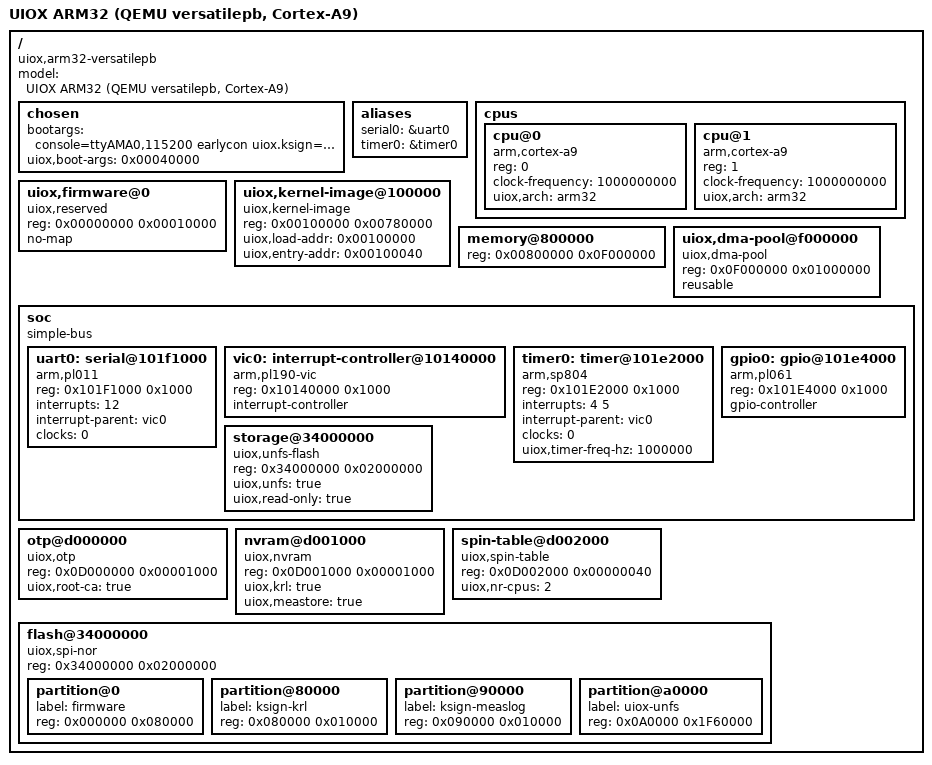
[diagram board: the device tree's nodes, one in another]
/*
 * uiox-arm32.dts — UIOX device tree source for ARM32
 *
 * Target: ARMv7-A, QEMU -machine versatilepb, Cortex-A9
 * Interrupt controller: PL190 VIC @ 0x10140000 (versatilepb)
 * Timer: SP804 dual timer @ 0x101E2000
 *
 * UIOX-specific regions (from UIOX source cross-references):
 *   kernel load/entry  ← uiox_ksign_image.h
 *   OTP/KRL/NVRAM      ← uiox_ksign_key.h
 *   SMP spin-table     ← uiox_cpu_hw.h
 *
 * Build:  make arm32      (or: dtc -I dts -O dtb -o uiox-arm32.dtb uiox-arm32.dts)
 *
 * Conventions: unit addresses are bare lowercase hex (no "0x", no leading 0s).
 */

/dts-v1/;

/ {
    model = "UIOX ARM32 (QEMU versatilepb, Cortex-A9)";
    compatible = "uiox,arm32-versatilepb";

    #address-cells = <1>;
    #size-cells    = <1>;

    chosen {
        /* UIOX bootargs — replaces the hardcoded string in
         * uiox_boot_main.c (UIOX_CMDLINE). */
        bootargs = "console=ttyAMA0,115200 earlycon uiox.ksign=on";
        /* Physical address the bootloader hands the kernel. */
        uiox,boot-args = <0x00040000>;
    };

    aliases {
        serial0 = &uart0;
        timer0  = &timer0;
    };

    /* ── CPUs ───────────────────────────────────────────────────── */
    cpus {
        #address-cells = <1>;
        #size-cells    = <0>;

        cpu@0 {
            device_type  = "cpu";
            compatible   = "arm,cortex-a9";
            reg          = <0>;
            clock-frequency = <1000000000>;   /* 1 GHz, QEMU default */
            uiox,arch    = "arm32";
        };

        cpu@1 {
            device_type  = "cpu";
            compatible   = "arm,cortex-a9";
            reg          = <1>;
            clock-frequency = <1000000000>;
            uiox,arch    = "arm32";
        };
    };

    /* ── Memory ─────────────────────────────────────────────────── */

    /* Trusted firmware / secure monitor region */
    uiox,firmware@0 {
        compatible = "uiox,reserved";
        reg = <0x00000000 0x00010000>;   /* 64 KiB secure/BL       */
        no-map;
    };

    /* UIOX kernel image — ksign verified (load = entry - 0x40) */
    uiox,kernel-image@100000 {
        compatible = "uiox,kernel-image";
        reg = <0x00100000 0x00780000>;   /* 7.5 MiB                */
        uiox,load-addr  = <0x00100000>;
        uiox,entry-addr = <0x00100040>;
    };

    /* OS usable RAM — placed above the kernel image so the addresses
     * do not collide (the earlier tree overlapped both at 0x100000). */
    memory@800000 {
        device_type = "memory";
        reg = <0x00800000 0x0F000000>;   /* 240 MiB (versatilepb)  */
    };

    /* DMA coherent pool */
    uiox,dma-pool@f000000 {
        compatible = "uiox,dma-pool";
        reg = <0x0F000000 0x01000000>;   /* 16 MiB                 */
        reusable;
    };

    /* ── SoC peripherals ────────────────────────────────────────── */
    soc {
        #address-cells = <1>;
        #size-cells    = <1>;
        compatible     = "simple-bus";
        ranges;

        /* PL011 UART0 — QEMU versatilepb @ 0x101F1000 */
        uart0: serial@101f1000 {
            compatible        = "arm,pl011", "arm,primecell";
            reg               = <0x101F1000 0x1000>;
            interrupts        = <12>;
            interrupt-parent  = <&vic0>;
            clocks            = <0>;
            status            = "okay";
        };

        /* PL190 Vectored Interrupt Controller @ 0x10140000 */
        vic0: interrupt-controller@10140000 {
            compatible        = "arm,pl190-vic", "arm,primecell";
            reg               = <0x10140000 0x1000>;
            interrupt-controller;
            #interrupt-cells  = <1>;
        };

        /* SP804 dual timer @ 0x101E2000 (timer0/timer1) */
        timer0: timer@101e2000 {
            compatible        = "arm,sp804", "arm,primecell";
            reg               = <0x101E2000 0x1000>;
            interrupts        = <4 5>;
            interrupt-parent  = <&vic0>;
            clocks            = <0>;
            /* UIOX: 1 MHz tick → 1 µs */
            uiox,timer-freq-hz = <1000000>;
        };

        /* System GPIO @ 0x101E4000 (versatilepb) */
        gpio0: gpio@101e4000 {
            compatible        = "arm,pl061", "arm,primecell";
            reg               = <0x101E4000 0x1000>;
            gpio-controller;
            #gpio-cells       = <2>;
        };

        /* UIOX native storage — NOR/flash window (see README partitions) */
        storage@34000000 {
            compatible = "uiox,unfs-flash";
            reg        = <0x34000000 0x02000000>;
            uiox,unfs      = "true";
            uiox,read-only = "true";
        };
    };

    /* ── UIOX security / boot subsystems ────────────────────────── */

    /* OTP / eFuse — root CA, burned in ROM (uiox_ksign_key.h) */
    otp@d000000 {
        compatible = "uiox,otp";
        reg        = <0x0D000000 0x00001000>;
        uiox,root-ca = "true";
        status     = "okay";
    };

    /* NVRAM — key revocation list (uiox_ksign_key.h) */
    nvram@d001000 {
        compatible = "uiox,nvram";
        reg        = <0x0D001000 0x00001000>;
        uiox,krl      = "true";
        uiox,meastore = "true";
    };

    /* SMP spin-table (uiox_cpu_hw.h) */
    spin-table@d002000 {
        compatible   = "uiox,spin-table";
        reg          = <0x0D002000 0x00000040>;
        uiox,nr-cpus = <2>;
    };

    /* ── Flash partition table ──────────────────────────────────── */
    flash@34000000 {
        compatible = "uiox,spi-nor";
        reg        = <0x34000000 0x02000000>;
        #address-cells = <1>;
        #size-cells    = <1>;

        partition@0 {
            label = "firmware";      /* 512 KiB */
            reg   = <0x000000 0x080000>;
        };
        partition@80000 {
            label = "ksign-krl";     /* 64 KiB  */
            reg   = <0x080000 0x010000>;
        };
        partition@90000 {
            label = "ksign-measlog"; /* 64 KiB  */
            reg   = <0x090000 0x010000>;
        };
        partition@a0000 {
            label = "uiox-unfs";     /* UNFS volume */
            reg   = <0x0A0000 0x1F60000>;
        };
    };
};
